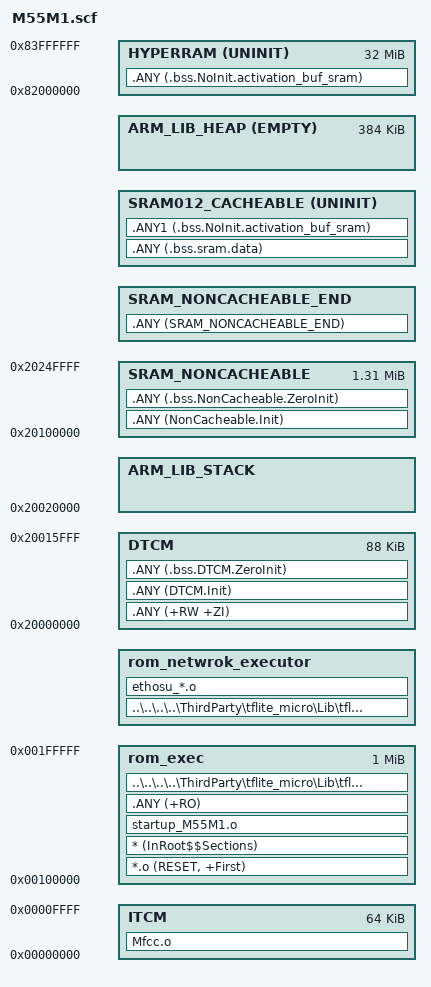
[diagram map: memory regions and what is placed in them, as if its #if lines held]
#! armclang -E --target=arm-arm-none-eabi -mcpu=cortex-m55 -xc
; command above MUST be in first line (no comment above!)

; Note: If any modification needed, please copy to local project folder first.

/*
 * Copyright (c) 2019-2021 Arm Limited. All rights reserved.
 *
 * SPDX-License-Identifier: Apache-2.0
 *
 * Licensed under the Apache License, Version 2.0 (the License); you may
 * not use this file except in compliance with the License.
 * You may obtain a copy of the License at
 *
 * www.apache.org/licenses/LICENSE-2.0
 *
 * Unless required by applicable law or agreed to in writing, software
 * distributed under the License is distributed on an AS IS BASIS, WITHOUT
 * WARRANTIES OR CONDITIONS OF ANY KIND, either express or implied.
 * See the License for the specific language governing permissions and
 * limitations under the License.
 */

/*
 *
 * +-----------------------+-------------+-------------+----+------------------------------------------------+
 * |  Memory region name   | Base addr   |    Size     |IDAU| Description                                    |
 * +-----------------------+-------------+-------------+----+------------------------------------------------+
 * | ITCM                  | 0x0000_0000 | 0x0001_0000 | S  | 64 kiB.                                        |
 * | ITCM                  | 0x1000_0000 | 0x0001_0000 | NS | Non-Secure alias for ITCM                      |
 * | FLASH                 | 0x0010_0000 | 0x0020_0000 | S  | 2 MiB                                          |
 * | FLASH                 | 0x1010_0000 | 0x0020_0000 | NS | Non-Secure alias for Flash                     |
 * | DTCM                  | 0x2000_0000 | 0x0002_0000 | S  | 128 kiB                                        |
 * | DTCM                  | 0x3000_0000 | 0x0002_0000 | NS | Non-Secure alias for DTCM                      |
 * | SRAM01                | 0x2010_0000 | 0x0010_0000 | S  | 1 MiB                                          |
 * | SRAM01                | 0x3010_0000 | 0x0010_0000 | NS | Non-Secure alias for SRAM01                    |
 * | SRAM2                 | 0x2020_0000 | 0x0005_0000 | S  | 320 kiB                                        |
 * | SRAM2                 | 0x3020_0000 | 0x0005_0000 | NS | Non-Secure alias for SRAM2                     |
 * | SRAM3                 | 0x2030_0000 | 0x0002_0000 | S  | 8 kiB                                          |
 * | SRAM3                 | 0x3030_0000 | 0x0002_0000 | NS | Non-Secure alias for SRAM3                     |
 * | LPSRAM                | 0x2031_0000 | 0x0002_0000 | S  | 8 kiB                                          |
 * | LPSRAM                | 0x3031_0000 | 0x0002_0000 | NS | Non-Secure alias for LPSRAM                    |
 * | EBI                   | 0x6000_0000 | 0x0030_0000 | S  | 3 MiB                                          |
 * | EBI                   | 0x7000_0000 | 0x0030_0000 | NS | Non-Secure alias for EBI                       |
 * | SPIM0                 | 0x8200_0000 | 0x0200_0000 | S  | 32 MiB                                         |
 * | SPIM0                 | 0x9200_0000 | 0x0200_0000 | NS | Non-Secure alias for SPIM0                     |
 * +-----------------------+-------------+-------------+----+------------------------------------------------+
 *
 *  Note: Ethos-U55 can access Flash, internal SRAM 0,1 => activation buffers and
 *        the model should only be placed in those regions.
 *
 *  Note: Alias regions means that secure and non-secure addresses are mapped to the same physical
 *        memory banks.
 */

#ifndef STACK_SIZE
#define STACK_SIZE 0xa000
#endif

#ifndef HEAP_SIZE
#define HEAP_SIZE  0x60000
#endif

#define ITCM_START      0x00000000
#define ITCM_SIZE       0x00010000
#define DTCM_START      0x20000000
#define DTCM_SIZE       0x00020000

#define FLASH_START     0x00100000
#define FLASH_SIZE      0x00100000

/* SRAM012 */
#define SRAM012_START    0x20100000
#define SRAM012_SIZE     0x00150000

#define SPIM0_START      0x82000000
#define SPIM0_SIZE       0x02000000


#define __RO_BASE           ( FLASH_START )
#define __RO_SIZE           ( FLASH_SIZE - TZ_NSC_SIZE )

#define __RW_BASE           ( DTCM_START )
#define __RW_SIZE           ( DTCM_SIZE - STACK_SIZE - HEAP_SIZE )

/*----------------------------------------------------------------------------
  User Stack & Heap boundary definition
 *----------------------------------------------------------------------------*/
#define __STACK_TOP    (DTCM_START + DTCM_SIZE - __STACKSEAL_SIZE)  /* starts at end of RAM - 8 byte stack seal */
#define __HEAP_BASE    (AlignExpr(+0, 8))                               /* starts after RW_RAM section, 8 byte aligned */

/* ----------------------------------------------------------------------------
  Stack seal size definition
 *----------------------------------------------------------------------------*/
#define __STACKSEAL_SIZE   ( 0 )

APP_IMAGE FLASH_START FLASH_SIZE
{
    ; Flash 2 MB
    rom_exec FLASH_START FLASH_SIZE
    {
        *.o (RESET, +First)
        * (InRoot$$Sections)
        ; Make sure reset_handler ends up in root segment
        startup_M55M1.o
        .ANY (+RO)
		..\..\..\..\ThirdParty\tflite_micro\Lib\tflu.lib (.init_array)
	}
	rom_netwrok_executor +0
	{
		..\..\..\..\ThirdParty\tflite_micro\Lib\tflu.lib (+RO)
		ethosu_*.o
	}

    ITCM ITCM_START ITCM_SIZE
    {
		Mfcc.o
    }

	; DTCM 128 KB shared with SRAM2
    ; Only accessible from the Cortex-M
#if (DTCM_SIZE > (STACK_SIZE  + __STACKSEAL_SIZE))
	DTCM DTCM_START (DTCM_SIZE - STACK_SIZE - __STACKSEAL_SIZE)
    {
        .ANY (+RW +ZI)
        .ANY (DTCM.Init)
        .ANY (.bss.DTCM.ZeroInit)
    }
#endif

    SRAM_NONCACHEABLE SRAM012_START SRAM012_SIZE
    {
        .ANY (NonCacheable.Init)
        .ANY (.bss.NonCacheable.ZeroInit)
    }
    ; Empty section to get maximum size of NonCacheable region with Image$$SRAM_NONCACHEABLE_END$$Base
    SRAM_NONCACHEABLE_END AlignExpr(+0, 1024)
    {
        .ANY (SRAM_NONCACHEABLE_END)
    }
    SRAM012_CACHEABLE AlignExpr(+0, 32) UNINIT
    {
        .ANY (.bss.sram.data)
        ; Place tensor arena in SRAM if we do not have a fast memory area
        .ANY1 (.bss.NoInit.activation_buf_sram)
    }

    ; Check SRAM size overflow here and ImageLength is uncompressed size
    ScatterAssert((ImageLength(SRAM_NONCACHEABLE) + ImageLength(SRAM012_CACHEABLE)) < (SRAM012_SIZE))

#if HEAP_SIZE > 0
    ARM_LIB_HEAP  __HEAP_BASE EMPTY  HEAP_SIZE {}		; Reserve empty region for heap
#endif

    HYPERRAM SPIM0_START UNINIT SPIM0_SIZE
    {
        ; Place tensor arena in SRAM if we do not have a fast memory area
        .ANY (.bss.NoInit.activation_buf_sram)
    }

    ARM_LIB_STACK __STACK_TOP EMPTY - STACK_SIZE {}     ; Reserve empty region for stack
}
	
